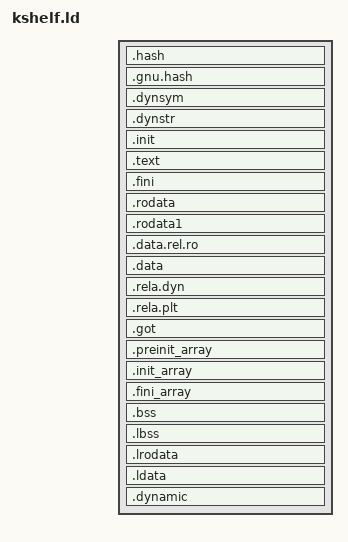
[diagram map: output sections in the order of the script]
/* kSHELF linker script, based on the original SHELF linker script but with a
 * with quite a few changes at this point.
 * Using three PHDRS:
 * * text for read / execute things
 * * data for read / write thigns
 * * dynamic for PT_DYNAMIC.
 *
 * I'm far from an expert on linker scripts, so this may have issues but it
 * works for now.
 */
/* Copyright (C) 2014-2019 Free Software Foundation, Inc.
   Copying and distribution of this script, with or without modification,
   are permitted in any medium without royalty provided the copyright
   notice and this notice are preserved.  */
OUTPUT_FORMAT("elf64-x86-64", "elf64-x86-64",
              "elf64-x86-64")
OUTPUT_ARCH(i386:x86-64)
ENTRY(_start)
PHDRS {
    text      PT_LOAD FILEHDR PHDRS;
    data      PT_LOAD;
    dynamic   PT_DYNAMIC;
}
SECTIONS
{
  /* Read-only sections, merged into text segment: */
  PROVIDE (__executable_start = SEGMENT_START("text-segment", 0)); 
  . = SEGMENT_START("text-segment", 0) + SIZEOF_HEADERS;
  .hash           : { *(.hash) } :text
  .gnu.hash       : { *(.gnu.hash) } :text
  .dynsym         : { *(.dynsym) } :text
  .dynstr         : { *(.dynstr) }  :text

  .init           :
  {
    KEEP (*(SORT_NONE(.init)))
  } :text
  .text           :
  {
    *(.text.unlikely .text.*_unlikely .text.unlikely.*)
    *(.text.exit .text.exit.*)
    *(.text.startup .text.startup.*)
    *(.text.hot .text.hot.*)
    *(.text .stub .text.* .gnu.linkonce.t.*)
    /* .gnu.warning sections are handled specially by elf32.em.  */
    *(.gnu.warning)
  } :text
  .fini           :
  {
    KEEP (*(SORT_NONE(.fini)))
  } :text
  PROVIDE (__etext = .);
  PROVIDE (_etext = .);
  PROVIDE (etext = .);
  .rodata         : { *(.rodata .rodata.* .gnu.linkonce.r.*) } :text
  .rodata1        : { *(.rodata1) } :text

  . = ALIGN(0x1000);

  /* Adjust the address for the data segment.  We want to adjust up to
     the same address within the page on the next page up.  */
  . = DATA_SEGMENT_ALIGN (CONSTANT (MAXPAGESIZE), CONSTANT (COMMONPAGESIZE));
  .data.rel.ro : { *(.data.rel.ro.local* .gnu.linkonce.d.rel.ro.local.*) *(.data.rel.ro .data.rel.ro.* .gnu.linkonce.d.rel.ro.*) } :data
  .data :
  {
    *(.data .data.* .gnu.linkonce.d.*)
  } :data
    .rela.dyn       :
    {
      *(.rela.init)
     *(.rela.text .rela.text.* .rela.gnu.linkonce.t.*)
      *(.rela.fini)
      *(.rela.rodata .rela.rodata.* .rela.gnu.linkonce.r.*)
      *(.rela.data .rela.data.* .rela.gnu.linkonce.d.*)
      *(.rela.tdata .rela.tdata.* .rela.gnu.linkonce.td.*)
      *(.rela.tbss .rela.tbss.* .rela.gnu.linkonce.tb.*)
      *(.rela.ctors)
      *(.rela.dtors)
      *(.rela.got)
      *(.rela.bss .rela.bss.* .rela.gnu.linkonce.b.*)
      *(.rela.ldata .rela.ldata.* .rela.gnu.linkonce.l.*)
      *(.rela.lbss .rela.lbss.* .rela.gnu.linkonce.lb.*)
      *(.rela.lrodata .rela.lrodata.* .rela.gnu.linkonce.lr.*)
      *(.rela.ifunc)
    } :data
  .rela.plt       :
    {
      *(.rela.plt)
      *(.rela.iplt)
    } : data
  .got : { *(.got.plt) *(.igot.plt) *(.got) *(.igot) } :data
    .preinit_array    :
  {
    PROVIDE_HIDDEN (__preinit_array_start = .);
    KEEP (*(.preinit_array))
    PROVIDE_HIDDEN (__preinit_array_end = .);
 } :data
    .init_array    :
  {
    PROVIDE_HIDDEN (__init_array_start = .);
    KEEP (*(SORT_BY_INIT_PRIORITY(.init_array.*) SORT_BY_INIT_PRIORITY(.ctors.*)))
    KEEP (*(.init_array EXCLUDE_FILE (*crtbegin.o *crtbegin?.o *crtend.o *crtend?.o ) .ctors))
    PROVIDE_HIDDEN (__init_array_end = .);
  } :data
  .fini_array    :
  {
    PROVIDE_HIDDEN (__fini_array_start = .);
    KEEP (*(SORT_BY_INIT_PRIORITY(.fini_array.*) SORT_BY_INIT_PRIORITY(.dtors.*)))
    KEEP (*(.fini_array EXCLUDE_FILE (*crtbegin.o *crtbegin?.o *crtend.o *crtend?.o ) .dtors))
    PROVIDE_HIDDEN (__fini_array_end = .);
  } :data
  _edata = .; PROVIDE (edata = .); 
  . = .;
  __bss_start = .;
  .bss            :
  {
   *(.dynbss)
   *(.bss .bss.* .gnu.linkonce.b.*)
   *(COMMON)
   /* Align here to ensure that the .bss section occupies space up to
      _end.  Align after .bss to ensure correct alignment even if the
      .bss section disappears because there are no input sections.
      FIXME: Why do we need it? When there is no .bss section, we do not
      pad the .data section.  */   
   . = ALIGN(. != 0 ? 64 / 8 : 1); 
  } :data
  .lbss   :
  {
    *(.dynlbss)
    *(.lbss .lbss.* .gnu.linkonce.lb.*)
    *(LARGE_COMMON)
  } :data
  . = ALIGN(64 / 8);
  . = SEGMENT_START("ldata-segment", .);
  .lrodata   ALIGN(CONSTANT (MAXPAGESIZE)) + (. & (CONSTANT (MAXPAGESIZE) - 1)) :
  {
    *(.lrodata .lrodata.* .gnu.linkonce.lr.*)
  } :data
  .ldata   ALIGN(CONSTANT (MAXPAGESIZE)) + (. & (CONSTANT (MAXPAGESIZE) - 1)) :
  {
    *(.ldata .ldata.* .gnu.linkonce.l.*)
    . = ALIGN(. != 0 ? 64 / 8 : 1);
  } :data
  . = ALIGN(64 / 8);
  _end = .; PROVIDE (end = .);
  . = DATA_SEGMENT_END (.);

  .dynamic : { *(.dynamic) } :dynamic

  /DISCARD/ : { *(.note.*) *(.gnu_debuglink) *(.gnu.lto_*)  *(.comment) *(.interp) }
}
